# ATxmega128B1 device description
Architecture: AVR8_XMEGA; Family: AVR XMEGA
Registers are 8-bit, access not given, no defined reset value unless marked. A register's access mark holds for its fields unless they carry their own. Offsets are from the block's base; [hi:lo] are bit positions; {n}, {i} and the like mark numbered series.

## AES — AES Module
Instances: AES 0x0C0
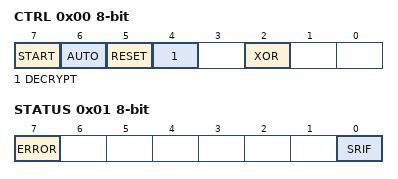
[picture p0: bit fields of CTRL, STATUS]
0x00 CTRL — AES Control Register
  [7] START — Start/Run
  [6] AUTO — Auto Start Trigger
  [5] RESET — AES Software Reset
  [4] DECRYPT — Decryption / Direction
  [2] XOR — State XOR Load Enable
0x01 STATUS — AES Status Register
  [7] ERROR — AES Error
  [0] SRIF — State Ready Interrupt Flag
0x02 STATE — AES State Register
0x03 KEY — AES Key Register
0x04 INTCTRL — AES Interrupt Control Register
  [1:0] INTLVL — Interrupt level
    0=OFF (Interrupt Disabled); 1=LO (Low Level); 2=MED (Medium Level); 3=HI (High Level)

## CRC — Cyclic Redundancy Checker
Instances: CRC 0x0D0
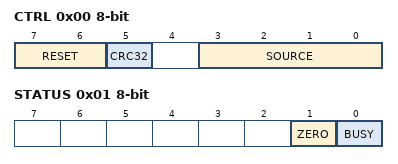
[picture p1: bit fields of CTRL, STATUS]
0x00 CTRL — Control Register
  [7:6] RESET
    0=NO (No Reset); 2=Reset CRC with CHECKSUM to all zeros; 3=Reset CRC with CHECKSUM to all ones
  [5] CRC32 — CRC Mode
  [3:0] SOURCE — Input Source
    0=DISABLE (Disabled); 1=IO (I/O Interface); 2=FLASH; 4=DMAC0 (DMAC Channel 0); 5=DMAC1 (DMAC Channel 1)
0x01 STATUS
  [1] ZERO — Zero detection
  [0] BUSY
0x03 DATAIN — Data Input
{0x4+i} CHECKSUM{i} (i=0..3) — Checksum byte {i}

## EVSYS — Event System
Instances: EVSYS 0x0180
{0x0+i} CH{i}MUX (i=0..3) — Event Channel {i} Multiplexer
  [7:0] CHMUX
    0=OFF; 8=RTC_OVF (RTC Overflow); 9=RTC_CMP (RTC Compare Match); 10=USB (USB Setup, SOF, CRC error and UNF/OVF); 16=ACA_CH0 (Analog Comparator A Channel 0); 17=ACA_CH1 (Analog Comparator A Channel 1); 18=ACA_WIN (Analog Comparator A Window); 19=ACB_CH0 (Analog Comparator B Channel 0); 20=ACB_CH1 (Analog Comparator B Channel 1); 21=ACB_WIN (Analog Comparator B Window); 32=ADCA_CH0 (ADC A Channel); 36=ADCB_CH0 (ADC B Channel); {v}=PORTA_PIN{v-80} (v=80..87); {v}=PORTB_PIN{v-88} (v=88..95); {v}=PORTC_PIN{v-96} (v=96..103); 104=PORTD_PIN0; 105=PORTD_PIN1; 106=PORTD_PIN2; {v}=PORTE_PIN{v-112} (v=112..119); 128=PRESCALER_1 (Prescaler, divide by 1); 129=PRESCALER_2 (Prescaler, divide by 2); 130=PRESCALER_4 (Prescaler, divide by 4); 131=PRESCALER_8 (Prescaler, divide by 8); 132=PRESCALER_16 (Prescaler, divide by 16); 133=PRESCALER_32 (Prescaler, divide by 32); 134=PRESCALER_64 (Prescaler, divide by 64); 135=PRESCALER_128 (Prescaler, divide by 128); 136=PRESCALER_256 (Prescaler, divide by 256); 137=PRESCALER_512 (Prescaler, divide by 512); 138=PRESCALER_1024 (Prescaler, divide by 1024); 139=PRESCALER_2048 (Prescaler, divide by 2048); 140=PRESCALER_4096 (Prescaler, divide by 4096); 141=PRESCALER_8192 (Prescaler, divide by 8192); 142=PRESCALER_16384 (Prescaler, divide by 16384); 143=PRESCALER_32768 (Prescaler, divide by 32768); 192=TCC0_OVF (Timer/Counter C0 Overflow); 193=TCC0_ERR (Timer/Counter C0 Error); 196=TCC0_CCA (Timer/Counter C0 Compare or Capture A); 197=TCC0_CCB (Timer/Counter C0 Compare or Capture B); 198=TCC0_CCC (Timer/Counter C0 Compare or Capture C); 199=TCC0_CCD (Timer/Counter C0 Compare or Capture D); 200=TCC1_OVF (Timer/Counter C1 Overflow); 201=TCC1_ERR (Timer/Counter C1 Error); 204=TCC1_CCA (Timer/Counter C1 Compare or Capture A); 205=TCC1_CCB (Timer/Counter C1 Compare or Capture B); 224=TCE0_OVF (Timer/Counter E0 Overflow); 225=TCE0_ERR (Timer/Counter E0 Error); 228=TCE0_CCA (Timer/Counter E0 Compare or Capture A); 229=TCE0_CCB (Timer/Counter E0 Compare or Capture B); 230=TCE0_CCC (Timer/Counter E0 Compare or Capture C); 231=TCE0_CCD (Timer/Counter E0 Compare or Capture D)
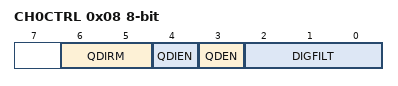
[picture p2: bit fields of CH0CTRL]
0x08 CH0CTRL — Channel 0 Control Register
  [6:5] QDIRM — Quadrature Decoder Index Recognition Mode
    0=QDPH0 = 0, QDPH90 = 0; 1=QDPH0 = 0, QDPH90 = 1; 2=QDPH0 = 1, QDPH90 = 0; 3=QDPH0 = 1, QDPH90 = 1
  [4] QDIEN — Quadrature Decoder Index Enable
  [3] QDEN — Quadrature Decoder Enable
  [2:0] DIGFILT — Digital Filter
    0=1SAMPLE; {v}={v+1}SAMPLES (v=1..7)
{0x8+i} CH{i}CTRL (i=1..3) — Channel {i} Control Register
  [2:0] DIGFILT — Digital Filter
    0=1SAMPLE; {v}={v+1}SAMPLES (v=1..7)
0x10 STROBE — Event Strobe
0x11 DATA — Event Data
